# CY8C5888LTI_LP097 register map
File version: 0.1
CY8C58LP
Registers are 8-bit, read-write, no defined reset value unless marked. A register's access mark holds for its fields unless they carry their own. Offsets are from the block's base; lines under a group give offsets from that group; [hi:lo] are bit positions; {n}, {i} and the like mark numbered series; 'fields as' and 'values as' point back to an identical list; <NAME> marks a mode.

## Memory map
0x00000000 ByteCounter
0x00000000 LEDDrive
0x00000000 ByteCountReset
0x00000000 Timer_1
0x00000000 TimerReset
0x00000000 UARTReset
0x00000000 LabVIEW_UART — UART

## ByteCounter
Base 0x00000000
0x40006408 ByteCounter_COUNTER — UDB.A0 - Current Counter Value
0x40006428 ByteCounter_PERIOD — UDB.D0 - Assigned Period
0x40006438 ByteCounter_COMPARE — UDB.D1 - Assigned Compare Value
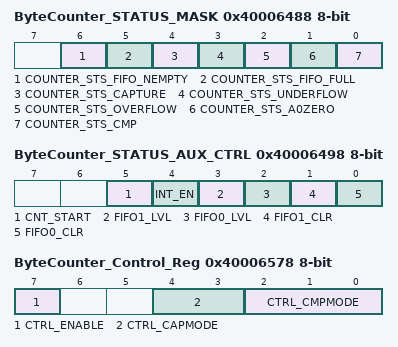
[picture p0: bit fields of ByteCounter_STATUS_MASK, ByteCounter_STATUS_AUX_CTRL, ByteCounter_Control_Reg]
0x40006488 ByteCounter_STATUS_MASK — UDB Status bits Interrupt Mask Enable Register
  [6] COUNTER_STS_FIFO_NEMPTY — FIFO Not Empty Status
  [5] COUNTER_STS_FIFO_FULL — FIFO Full Status
  [4] COUNTER_STS_CAPTURE — Capture Status
  [3] COUNTER_STS_UNDERFLOW — Underflow status
  [2] COUNTER_STS_OVERFLOW — Overflow status
  [1] COUNTER_STS_A0ZERO — A0 Zero ouput status
  [0] COUNTER_STS_CMP — Compare output status
0x40006498 ByteCounter_STATUS_AUX_CTRL — UDB Auxilliary Control Register
  [5] CNT_START — FIFO0 clear
    0=E_CNT_START0 (Disable counter); 1=E_CNT_START1 (Enable counter)
  [4] INT_EN
    0=E_INT_EN0 (Interrupt disabled); 1=E_INT_EN1 (Interrupt enabled)
  [3] FIFO1_LVL — FIFO level
    0=E_FIFO_LVL_0 (FIFO LVL: input mode: FIFO not full; output mode: FIFO not empty); 1=E_FIFO_LVL_1 (FIFO LVL: input mode: FIFO at least 1/2 empty; output mode: FIFO at least 1/2 full)
  [2] FIFO0_LVL — FIFO level
    values as FIFO1_LVL
  [1] FIFO1_CLR — FIFO1 clear
    0=E_FIFO_CLR_0 (Normal FIFO operation); 1=E_FIFO_CLR_1 (Clear FIFO state)
  [0] FIFO0_CLR — FIFO0 clear
    values as FIFO1_CLR
0x40006578 ByteCounter_Control_Reg — UDB Control Register - Assigned Control Register Value
  [7] CTRL_ENABLE — Enable Counter
  [4:3] CTRL_CAPMODE — Capture mode
  [2:0] CTRL_CMPMODE — Compare mode

## LEDDrive
Base 0x00000000
0x40006479 LEDDrive_CONTROL_REG

## ByteCountReset
Base 0x00000000
0x40006478 ByteCountReset_CONTROL_REG

## Timer_1
Base 0x00000000
0x40006504 Timer_1_COUNTER 16-bit — UDB.A0 - Current Down Counter Value
0x40006524 Timer_1_PERIOD 16-bit — UDB.D0 - Assigned Period
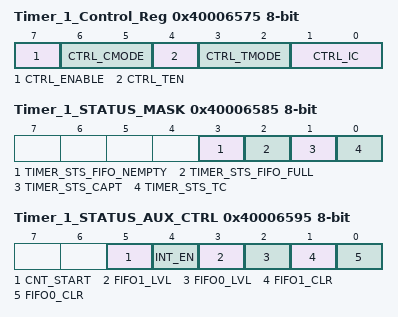
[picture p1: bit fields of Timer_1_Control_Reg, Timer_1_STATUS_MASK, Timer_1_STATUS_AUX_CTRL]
0x40006575 Timer_1_Control_Reg — UDB Control Register - Assigned Control Register Value
  [7] CTRL_ENABLE — Enable the Timer
  [6:5] CTRL_CMODE — Capture Mode
  [4] CTRL_TEN — Trigger Enable Bit
  [3:2] CTRL_TMODE — Trigger Mode
  [1:0] CTRL_IC — Interrupt Count
0x40006585 Timer_1_STATUS_MASK — UDB Status bits Interrupt Mask Enable Register
  [3] TIMER_STS_FIFO_NEMPTY ro — FIFO Empty status
  [2] TIMER_STS_FIFO_FULL ro — FIFO Full Status
  [1] TIMER_STS_CAPT ro — Enables the Interrupt on Capture
  [0] TIMER_STS_TC ro — Enables the Interrupt on TC
0x40006595 Timer_1_STATUS_AUX_CTRL — UDB Auxilliary Control Register
  fields as ByteCounter.ByteCounter_STATUS_AUX_CTRL

## TimerReset
Base 0x00000000
0x40006574 TimerReset_CONTROL_REG

## UARTReset
Base 0x00000000
0x40006579 UARTReset_CONTROL_REG

## LabVIEW_UART — UART
Base 0x00000000
0x40006529 RX_LabVIEW_UART_RX_ADDRESS1 — RX Address1 Register
0x40006539 RX_LabVIEW_UART_RX_ADDRESS2 — RX Address2 Register
0x40006549 RX_LabVIEW_UART_RX_DATA — RX Data Register
0x4000654B TX_LabVIEW_UART_TX_DATA — TX Data Register
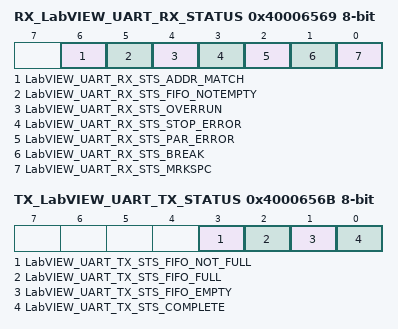
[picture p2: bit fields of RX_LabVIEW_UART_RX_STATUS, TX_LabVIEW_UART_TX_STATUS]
0x40006569 RX_LabVIEW_UART_RX_STATUS — RX status register
  [6] LabVIEW_UART_RX_STS_ADDR_MATCH ro, [5] LabVIEW_UART_RX_STS_FIFO_NOTEMPTY ro, [4] LabVIEW_UART_RX_STS_OVERRUN ro, [3] LabVIEW_UART_RX_STS_STOP_ERROR ro, [2] LabVIEW_UART_RX_STS_PAR_ERROR ro, [1] LabVIEW_UART_RX_STS_BREAK ro, [0] LabVIEW_UART_RX_STS_MRKSPC ro
0x4000656B TX_LabVIEW_UART_TX_STATUS — TX status register
  [3] LabVIEW_UART_TX_STS_FIFO_NOT_FULL ro, [2] LabVIEW_UART_TX_STS_FIFO_FULL ro, [1] LabVIEW_UART_TX_STS_FIFO_EMPTY ro, [0] LabVIEW_UART_TX_STS_COMPLETE ro
